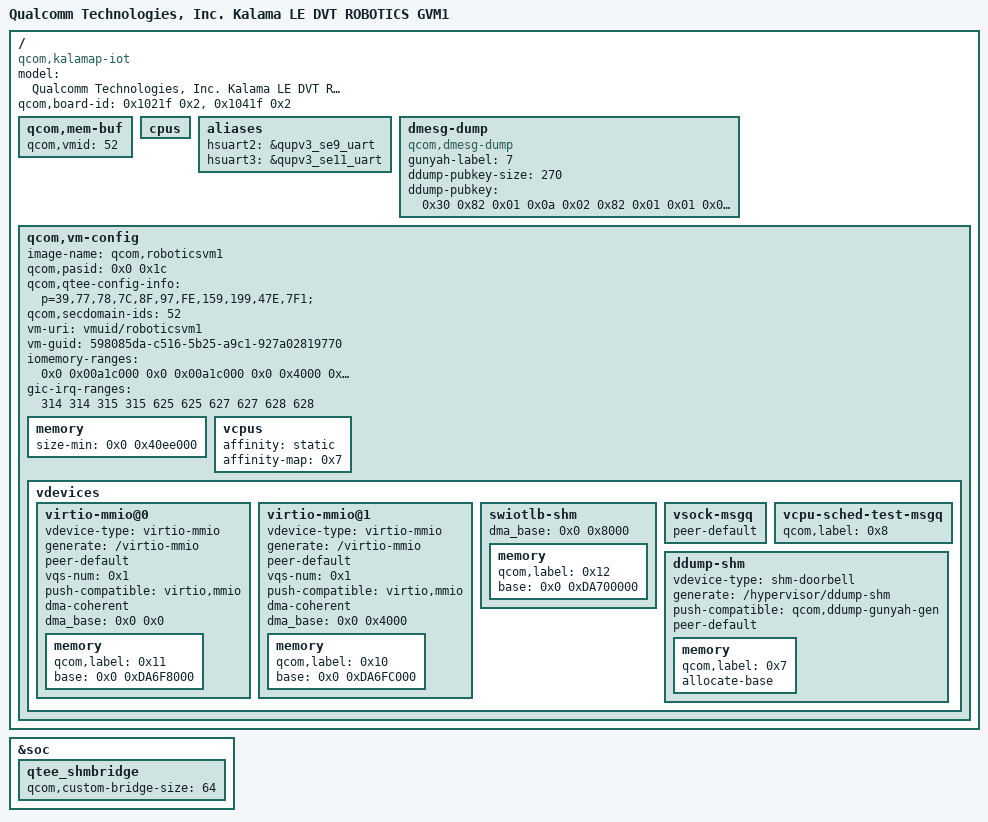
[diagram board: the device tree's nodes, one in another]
/dts-v1/;

#include "kalamale_roboticsvm.dtsi"
#include "kalamale_roboticsvm1-dvt.dtsi"

/ {
	model = "Qualcomm Technologies, Inc. Kalama LE DVT ROBOTICS GVM1";
	compatible = "qcom,kalamap-iot", "qcom,kalamap", "qcom,iot";
	qcom,board-id = <0x1021f 0x2>, <0x1041f 0x2>;

	qcom,mem-buf {
		qcom,vmid = <52>;
	};

	cpus {
		/delete-node/ cpu@100;
	};

	aliases: aliases {
		hsuart2 = &qupv3_se9_uart;
		hsuart3 = &qupv3_se11_uart;
	};

	dmesg-dump {
		compatible = "qcom,dmesg-dump";
		gunyah-label = <7>;
		ddump-pubkey-size = <270>;
		ddump-pubkey = /bits/ 8 <0x30 0x82 0x01 0x0a 0x02 0x82 0x01 0x01 0x00 0xe6 0x4b 0x31 0x82 0x61 0x14 0xf2
				0xbe 0xd1 0xe4 0xde 0xe7 0xed 0xba 0x8f 0x3b 0x23 0x5f 0x7a 0xb8 0x16 0x40 0x96
				0xae 0x77 0x5e 0x1b 0xf0 0x3f 0x39 0xab 0x69 0x90 0xb1 0xd4 0x70 0xcb 0x66 0xbc
				0x41 0x08 0x1d 0x37 0xdb 0x49 0xc8 0x49 0x5b 0x99 0x5c 0x32 0xbe 0x62 0xd5 0xa7
				0x3c 0x0f 0xa4 0x4b 0x43 0x49 0xdb 0x54 0x69 0x06 0x0c 0xe5 0x99 0xe5 0xf9 0x1e
				0x25 0x84 0x17 0x47 0x62 0x2b 0x5d 0x0d 0xec 0x5e 0xc6 0xb5 0x86 0xb9 0x75 0x6d
				0xfe 0x7d 0x35 0x4f 0x35 0xc1 0x48 0x10 0x75 0x4c 0x57 0x6b 0x46 0x4b 0xff 0x5b
				0x52 0x22 0x40 0x2c 0xb0 0x47 0xe1 0x47 0xc4 0xe5 0x47 0x0c 0x56 0xe8 0x17 0xd0
				0x7e 0xc3 0x4d 0x9f 0xea 0xd0 0xea 0x87 0xe5 0x51 0x39 0xe8 0x45 0x4c 0x54 0x27
				0x9c 0x50 0x38 0xb7 0x72 0x93 0x12 0x0b 0xa1 0x2f 0x9e 0x04 0x92 0x20 0x6e 0x31
				0x42 0x87 0xe1 0xfe 0x88 0x3f 0xe5 0x09 0xe1 0xf9 0xbe 0x44 0xc6 0xbf 0x10 0x79
				0x36 0x47 0x7b 0xa0 0x8e 0x27 0x31 0xa3 0x70 0x69 0x01 0x54 0x92 0xf4 0x42 0xbd
				0xcd 0x7e 0x79 0x2b 0x2c 0xe1 0xd4 0xba 0x6e 0x34 0xc6 0xe6 0xc6 0x5c 0x63 0xd0
				0x7f 0x39 0x1f 0xe8 0x8d 0x67 0xe6 0x27 0x67 0x0d 0x16 0x57 0x94 0xd1 0xfb 0xdf
				0xce 0xaf 0xfd 0x43 0xb3 0xbe 0x5d 0x83 0x4b 0x93 0x05 0xe8 0xdf 0x04 0xad 0xac
				0xeb 0xa6 0x81 0xa7 0xd5 0x04 0x63 0xbf 0x83 0xb8 0x0c 0xbc 0x20 0x18 0xb5 0x50
				0xd7 0x61 0x84 0x11 0xca 0x2d 0x22 0xb3 0x29 0x02 0x03 0x01 0x00 0x01>;
	};

	qcom,vm-config {
		image-name = "qcom,roboticsvm1";
		qcom,pasid = <0x0 0x1c>;
		qcom,qtee-config-info = "p=39,77,78,7C,8F,97,FE,159,199,47E,7F1;";
		qcom,secdomain-ids = <52>;
		vm-uri = "vmuid/roboticsvm1";
		vm-guid = "598085da-c516-5b25-a9c1-927a02819770";

		iomemory-ranges = <0x0 0x00a1c000 0x0 0x00a1c000 0x0 0x4000 0x0
				0x0 0x00a20000 0x0 0x00a20000 0x0 0x4000 0x0
				0x0 0x00824000 0x0 0x00824000 0x0 0x4000 0x0
				0x0 0x0082C000 0x0 0x0082C000 0x0 0x4000 0x0
				0x0 0x00830000 0x0 0x00830000 0x0 0x4000 0x0
				0x0 0x00a94000 0x0 0x00a94000 0x0 0x1000 0x0
				0x0 0x00a90000 0x0 0x00a90000 0x0 0x1000 0x0
				0x0 0x00880000 0x0 0x00880000 0x0 0x1000 0x0
				0x0 0x00884000 0x0 0x00884000 0x0 0x1000 0x0
				0x0 0x0088c000 0x0 0x0088c000 0x0 0x1000 0x0>;

		gic-irq-ranges = <314 314
				315 315
				625 625
				627 627
				628 628>;

		memory {
			size-min = <0x0 0x40ee000>;    /* 64 MB */
		};

		vcpus {
			affinity = "static";
			affinity-map = <0x7>;
		};

		vdevices {
			virtio-mmio@0 {
				vdevice-type = "virtio-mmio";
				generate = "/virtio-mmio";
				peer-default;
				vqs-num = <0x1>;
				push-compatible = "virtio,mmio";
				dma-coherent;
				dma_base = <0x0 0x0>;
				memory {
					qcom,label = <0x11>;
					#address-cells = <0x2>;
					base = <0x0 0xDA6F8000>;
				};
			};

			virtio-mmio@1 {
				vdevice-type = "virtio-mmio";
				generate = "/virtio-mmio";
				peer-default;
				vqs-num = <0x1>;
				push-compatible = "virtio,mmio";
				dma-coherent;
				dma_base = <0x0 0x4000>;
				memory {
					qcom,label = <0x10>;
					#address-cells = <0x2>;
					base = <0x0 0xDA6FC000>;
				};
			};

			swiotlb-shm {
				dma_base = <0x0 0x8000>;
				memory {
					qcom,label = <0x12>;
					#address-cells = <0x2>;
					base = <0x0 0xDA700000>;
				};
			};

			vsock-msgq {
				peer-default;
				/delete-property/ peer;
			};

			vcpu-sched-test-msgq {
				qcom,label = <0x8>;
			};

			ddump-shm {
				vdevice-type = "shm-doorbell";
				generate = "/hypervisor/ddump-shm";
				push-compatible = "qcom,ddump-gunyah-gen";
				peer-default;
				memory {
					qcom,label = <0x7>;
					allocate-base;
				};
			};
		};
	};
};

&soc {
	qtee_shmbridge {
		qcom,custom-bridge-size = <64>;
	};
};
